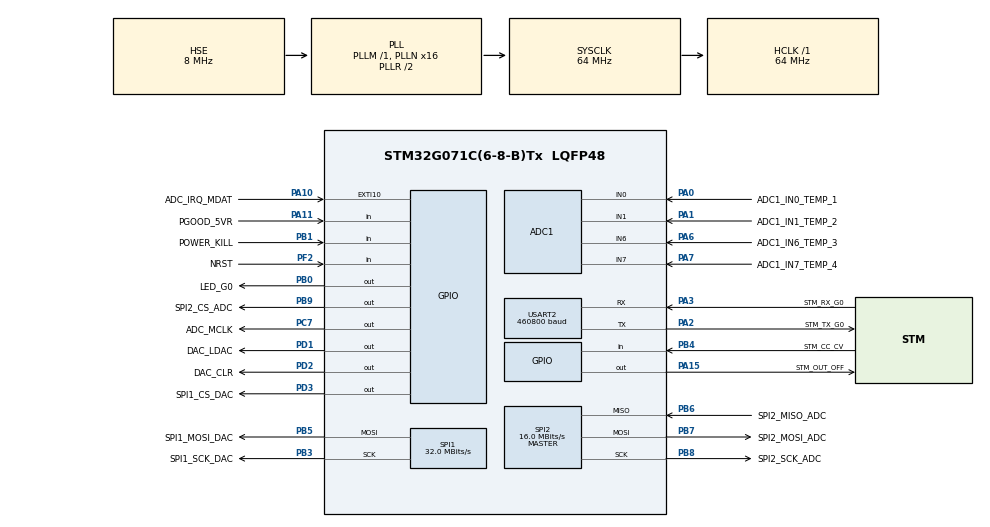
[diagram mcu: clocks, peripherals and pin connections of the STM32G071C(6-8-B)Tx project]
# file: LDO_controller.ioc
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ADC1.Channel-2\#ChannelRegularConversion=ADC_CHANNEL_0
ADC1.NbrOfConversionFlag=1
ADC1.Rank-2\#ChannelRegularConversion=1
ADC1.SamplingTime-2\#ChannelRegularConversion=ADC_SAMPLINGTIME_COMMON_1
ADC1.SelectedChannel=ADC_CHANNEL_0|ADC_CHANNEL_1|ADC_CHANNEL_6|ADC_CHANNEL_7
ADC1.master=1
Mcu.Family=STM32G0
Mcu.Name=STM32G071C(6-8-B)Tx
Mcu.Package=LQFP48
NVIC.EXTI4_15_IRQn=true\:1\:0\:false\:false\:true\:true\:true\:true
NVIC.USART2_IRQn=true\:1\:0\:false\:false\:true\:true\:true\:true
PA0.GPIO_Label=ADC1_IN0_TEMP_1
PA0.Mode=IN0
PA0.Signal=ADC1_IN0
PA1.GPIO_Label=ADC1_IN1_TEMP_2
PA1.Mode=IN1
PA1.Signal=ADC1_IN1
PA10.GPIO_Label=ADC_IRQ_MDAT
PA10.GPIO_ModeDefaultEXTI=GPIO_MODE_IT_FALLING
PA10.GPIO_PuPd=GPIO_PULLUP
PA10.Signal=GPXTI10
PA11\ [PA9].GPIO_Label=PGOOD_5VR
PA11\ [PA9].GPIO_PuPd=GPIO_NOPULL
PA11\ [PA9].Signal=GPIO_Input
PA13.GPIO_Label=SWDIO_G0
PA13.Mode=Serial_Wire
PA13.Signal=SYS_SWDIO
PA14-BOOT0.GPIO_Label=SWCLK_G0
PA14-BOOT0.Mode=Serial_Wire
PA14-BOOT0.Signal=SYS_SWCLK
PA15.GPIO_Label=STM_OUT_OFF
PA15.PinState=GPIO_PIN_SET
PA15.Signal=GPIO_Output
PA2.GPIO_Label=STM_TX_G0
PA2.Mode=Asynchronous
PA2.Signal=USART2_TX
PA3.GPIO_Label=STM_RX_G0
PA3.Mode=Asynchronous
PA3.Signal=USART2_RX
PA6.GPIO_Label=ADC1_IN6_TEMP_3
PA6.Mode=IN6
PA6.Signal=ADC1_IN6
PA7.GPIO_Label=ADC1_IN7_TEMP_4
PA7.Mode=IN7
PA7.Signal=ADC1_IN7
PB0.GPIO_Label=LED_G0
PB0.PinState=GPIO_PIN_SET
PB0.Signal=GPIO_Output
PB1.GPIO_Label=POWER_KILL
PB1.GPIO_PuPd=GPIO_PULLUP
PB1.Signal=GPIO_Input
PB3.GPIO_Label=SPI1_SCK_DAC
PB3.Mode=TX_Only_Simplex_Unidirect_Master
PB3.Signal=SPI1_SCK
PB4.GPIO_Label=STM_CC_CV
PB4.Signal=GPIO_Input
PB5.GPIO_Label=SPI1_MOSI_DAC
PB5.Mode=TX_Only_Simplex_Unidirect_Master
PB5.Signal=SPI1_MOSI
PB6.GPIO_Label=SPI2_MISO_ADC
PB6.Mode=Full_Duplex_Master
PB6.Signal=SPI2_MISO
PB7.GPIO_Label=SPI2_MOSI_ADC
PB7.Mode=Full_Duplex_Master
PB7.Signal=SPI2_MOSI
PB8.GPIO_Label=SPI2_SCK_ADC
PB8.Mode=Full_Duplex_Master
PB8.Signal=SPI2_SCK
PB9.GPIO_FM9=__NULL
PB9.GPIO_Label=SPI2_CS_ADC
PB9.GPIO_Speed=GPIO_SPEED_FREQ_MEDIUM
PB9.PinState=GPIO_PIN_SET
PB9.Signal=GPIO_Output
PC7.GPIO_Label=ADC_MCLK
PC7.Signal=GPIO_Output
PD1.GPIO_Label=DAC_LDAC
PD1.PinState=GPIO_PIN_SET
PD1.Signal=GPIO_Output
PD2.GPIO_Label=DAC_CLR
PD2.PinState=GPIO_PIN_SET
PD2.Signal=GPIO_Output
PD3.GPIO_Label=SPI1_CS_DAC
PD3.GPIO_Speed=GPIO_SPEED_FREQ_MEDIUM
PD3.PinState=GPIO_PIN_SET
PD3.Signal=GPIO_Output
PF0-OSC_IN\ (PF0).Mode=HSE-External-Oscillator
PF0-OSC_IN\ (PF0).Signal=RCC_OSC_IN
PF1-OSC_OUT\ (PF1).Mode=HSE-External-Oscillator
PF1-OSC_OUT\ (PF1).Signal=RCC_OSC_OUT
PF2\ -\ NRST.GPIO_Label=NRST
PF2\ -\ NRST.Signal=GPIO_Input
ProjectManager.HeapSize=0x400
ProjectManager.StackSize=0x800
ProjectManager.TargetToolchain=CMake
RCC.ADCFreq_Value=64000000
RCC.AHBFreq_Value=64000000
RCC.CortexFreq_Value=64000000
RCC.EXTERNAL_CLOCK_VALUE=48000
RCC.HCLKFreq_Value=64000000
RCC.HSE_VALUE=8000000
RCC.HSI_VALUE=16000000
RCC.LSE_VALUE=32768
RCC.PLLN=16
RCC.PLLSourceVirtual=RCC_PLLSOURCE_HSE
RCC.SYSCLKFreq_VALUE=64000000
RCC.SYSCLKSource=RCC_SYSCLKSOURCE_PLLCLK
RCC.VCOOutputFreq_Value=128000000
SPI1.BaudRatePrescaler=SPI_BAUDRATEPRESCALER_2
SPI1.CLKPhase=SPI_PHASE_2EDGE
SPI1.CalculateBaudRate=32.0 MBits/s
SPI1.DataSize=SPI_DATASIZE_8BIT
SPI1.Direction=SPI_DIRECTION_1LINE
SPI1.Mode=SPI_MODE_MASTER
SPI1.NSSPMode=SPI_NSS_PULSE_DISABLE
SPI1.VirtualType=VM_MASTER
SPI2.BaudRatePrescaler=SPI_BAUDRATEPRESCALER_4
SPI2.CalculateBaudRate=16.0 MBits/s
SPI2.DataSize=SPI_DATASIZE_8BIT
SPI2.Direction=SPI_DIRECTION_2LINES
SPI2.Mode=SPI_MODE_MASTER
SPI2.NSSPMode=SPI_NSS_PULSE_DISABLE
SPI2.VirtualType=VM_MASTER
USART2.BaudRate=460800
USART2.Parity=PARITY_NONE
USART2.VirtualMode-Asynchronous=VM_ASYNC
USART2.WordLength=WORDLENGTH_8B
VP_SYS_V_VREFBUF.Mode=ExternalMode
board=custom

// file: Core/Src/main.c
/* USER CODE BEGIN Header */
/**
  ******************************************************************************
  * @file           : main.c
  * @brief          : Main program body
  ******************************************************************************
  * @attention
  *
  * Copyright (c) 2026 STMicroelectronics.
  * All rights reserved.
  *
  * This software is licensed under terms that can be found in the LICENSE file
  * in the root directory of this software component.
  * If no LICENSE file comes with this software, it is provided AS-IS.
  *
  ******************************************************************************
  */
/* USER CODE END Header */
#include "main.h"
#include "adc.h"
#include "spi.h"
#include "usart.h"
#include "gpio.h"

/* USER CODE BEGIN Includes */
#include "app.h"

/* USER CODE END Includes */

void SystemClock_Config(void);

int main(void)
{

  /* MCU Configuration--------------------------------------------------------*/

  /* Reset of all peripherals, Initializes the Flash interface and the Systick. */
  HAL_Init();

  /* Configure the system clock */
  SystemClock_Config();

  /* Initialize all configured peripherals */
  MX_GPIO_Init();
  MX_ADC1_Init();
  MX_SPI1_Init();
  MX_SPI2_Init();
  MX_USART2_UART_Init();
  /* USER CODE BEGIN 2 */
  APP_Init();

  /* USER CODE END 2 */

  /* Infinite loop */
  while (1)
  {

    /* USER CODE BEGIN 3 */
    APP_Task();
  }
  /* USER CODE END 3 */
}

void SystemClock_Config(void)
{
  RCC_OscInitTypeDef RCC_OscInitStruct = {0};
  RCC_ClkInitTypeDef RCC_ClkInitStruct = {0};

  /** Configure the main internal regulator output voltage
  */
  HAL_PWREx_ControlVoltageScaling(PWR_REGULATOR_VOLTAGE_SCALE1);

  /** Initializes the RCC Oscillators according to the specified parameters
  * in the RCC_OscInitTypeDef structure.
  */
  RCC_OscInitStruct.OscillatorType = RCC_OSCILLATORTYPE_HSE;
  RCC_OscInitStruct.HSEState = RCC_HSE_ON;
  RCC_OscInitStruct.PLL.PLLState = RCC_PLL_ON;
  RCC_OscInitStruct.PLL.PLLSource = RCC_PLLSOURCE_HSE;
  RCC_OscInitStruct.PLL.PLLM = RCC_PLLM_DIV1;
  RCC_OscInitStruct.PLL.PLLN = 16;
  RCC_OscInitStruct.PLL.PLLP = RCC_PLLP_DIV2;
  RCC_OscInitStruct.PLL.PLLQ = RCC_PLLQ_DIV2;
  RCC_OscInitStruct.PLL.PLLR = RCC_PLLR_DIV2;
  if (HAL_RCC_OscConfig(&RCC_OscInitStruct) != HAL_OK)
  {
    Error_Handler();
  }

  /** Initializes the CPU, AHB and APB buses clocks
  */
  RCC_ClkInitStruct.ClockType = RCC_CLOCKTYPE_HCLK|RCC_CLOCKTYPE_SYSCLK
                              |RCC_CLOCKTYPE_PCLK1;
  RCC_ClkInitStruct.SYSCLKSource = RCC_SYSCLKSOURCE_PLLCLK;
  RCC_ClkInitStruct.AHBCLKDivider = RCC_SYSCLK_DIV1;
  RCC_ClkInitStruct.APB1CLKDivider = RCC_HCLK_DIV1;

  if (HAL_RCC_ClockConfig(&RCC_ClkInitStruct, FLASH_LATENCY_2) != HAL_OK)
  {
    Error_Handler();
  }
}

void Error_Handler(void)
{
  __disable_irq();
  while (1)
  {
  }
}
